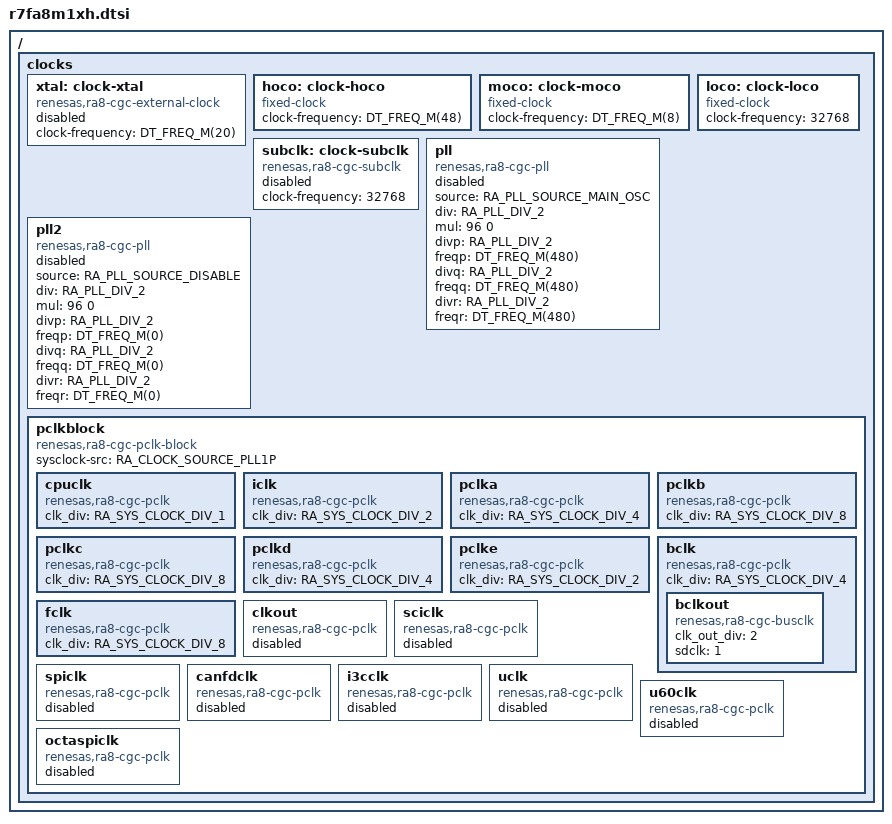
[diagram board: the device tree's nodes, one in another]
/*
 * Copyright (c) 2024 Renesas Electronics Corporation
 *
 * SPDX-License-Identifier: Apache-2.0
 */

#include <arm/renesas/ra/ra8/ra8x1.dtsi>
#include <zephyr/dt-bindings/clock/ra_clock.h>

/ {
	clocks: clocks {
		xtal: clock-xtal {
			compatible = "renesas,ra8-cgc-external-clock";
			clock-frequency = <DT_FREQ_M(20)>;
			#clock-cells = <0>;
			status = "disabled";
		};

		hoco: clock-hoco {
			compatible = "fixed-clock";
			clock-frequency = <DT_FREQ_M(48)>;
			#clock-cells = <0>;
		};

		moco: clock-moco {
			compatible = "fixed-clock";
			clock-frequency = <DT_FREQ_M(8)>;
			#clock-cells = <0>;
		};

		loco: clock-loco {
			compatible = "fixed-clock";
			clock-frequency = <32768>;
			#clock-cells = <0>;
		};

		subclk: clock-subclk {
			compatible = "renesas,ra8-cgc-subclk";
			clock-frequency = <32768>;
			#clock-cells = <0>;
			status = "disabled";
		};

		pll: pll {
			compatible = "renesas,ra8-cgc-pll";
			#clock-cells = <0>;

			/* PLL */
			source = <RA_PLL_SOURCE_MAIN_OSC>;
			div = <RA_PLL_DIV_2>;
			mul = <96 0>;
			divp = <RA_PLL_DIV_2>;
			freqp = <DT_FREQ_M(480)>;
			divq = <RA_PLL_DIV_2>;
			freqq = <DT_FREQ_M(480)>;
			divr = <RA_PLL_DIV_2>;
			freqr = <DT_FREQ_M(480)>;
			status = "disabled";
		};

		pll2: pll2 {
			compatible = "renesas,ra8-cgc-pll";
			#clock-cells = <0>;

			/* PLL2 */
			source = <RA_PLL_SOURCE_DISABLE>;
			div = <RA_PLL_DIV_2>;
			mul = <96 0>;
			divp = <RA_PLL_DIV_2>;
			freqp = <DT_FREQ_M(0)>;
			divq = <RA_PLL_DIV_2>;
			freqq = <DT_FREQ_M(0)>;
			divr = <RA_PLL_DIV_2>;
			freqr = <DT_FREQ_M(0)>;
			status = "disabled";
		};

		pclkblock: pclkblock {
			compatible = "renesas,ra8-cgc-pclk-block";
			#clock-cells = <0>;
			sysclock-src = <RA_CLOCK_SOURCE_PLL1P>;
			status = "okay";

			cpuclk: cpuclk {
				compatible = "renesas,ra8-cgc-pclk";
				clk_div = <RA_SYS_CLOCK_DIV_1>;
				#clock-cells = <2>;
				status = "okay";
			};

			iclk: iclk {
				compatible = "renesas,ra8-cgc-pclk";
				clk_div = <RA_SYS_CLOCK_DIV_2>;
				#clock-cells = <2>;
				status = "okay";
			};

			pclka: pclka {
				compatible = "renesas,ra8-cgc-pclk";
				clk_div = <RA_SYS_CLOCK_DIV_4>;
				#clock-cells = <2>;
				status = "okay";
			};

			pclkb: pclkb {
				compatible = "renesas,ra8-cgc-pclk";
				clk_div = <RA_SYS_CLOCK_DIV_8>;
				#clock-cells = <2>;
				status = "okay";
			};

			pclkc: pclkc {
				compatible = "renesas,ra8-cgc-pclk";
				clk_div = <RA_SYS_CLOCK_DIV_8>;
				#clock-cells = <2>;
				status = "okay";
			};

			pclkd: pclkd {
				compatible = "renesas,ra8-cgc-pclk";
				clk_div = <RA_SYS_CLOCK_DIV_4>;
				#clock-cells = <2>;
				status = "okay";
			};

			pclke: pclke {
				compatible = "renesas,ra8-cgc-pclk";
				clk_div = <RA_SYS_CLOCK_DIV_2>;
				#clock-cells = <2>;
				status = "okay";
			};

			bclk: bclk {
				compatible = "renesas,ra8-cgc-pclk";
				clk_div = <RA_SYS_CLOCK_DIV_4>;
				bclkout: bclkout {
					compatible = "renesas,ra8-cgc-busclk";
					clk_out_div = <2>;
					sdclk = <1>;
					#clock-cells = <0>;
				};
				#clock-cells = <2>;
				status = "okay";
			};

			fclk: fclk {
				compatible = "renesas,ra8-cgc-pclk";
				clk_div = <RA_SYS_CLOCK_DIV_8>;
				#clock-cells = <2>;
				status = "okay";
			};

			clkout: clkout {
				compatible = "renesas,ra8-cgc-pclk";
				#clock-cells = <2>;
				status = "disabled";
			};

			sciclk: sciclk {
				compatible = "renesas,ra8-cgc-pclk";
				#clock-cells = <2>;
				status = "disabled";
			};

			spiclk: spiclk {
				compatible = "renesas,ra8-cgc-pclk";
				#clock-cells = <2>;
				status = "disabled";
			};

			canfdclk: canfdclk {
				compatible = "renesas,ra8-cgc-pclk";
				#clock-cells = <2>;
				status = "disabled";
			};

			i3cclk: i3cclk {
				compatible = "renesas,ra8-cgc-pclk";
				#clock-cells = <2>;
				status = "disabled";
			};

			uclk: uclk {
				compatible = "renesas,ra8-cgc-pclk";
				#clock-cells = <2>;
				status = "disabled";
			};

			u60clk: u60clk {
				compatible = "renesas,ra8-cgc-pclk";
				#clock-cells = <2>;
				status = "disabled";
			};

			octaspiclk: octaspiclk {
				compatible = "renesas,ra8-cgc-pclk";
				#clock-cells = <2>;
				status = "disabled";
			};
		};
	};
};
